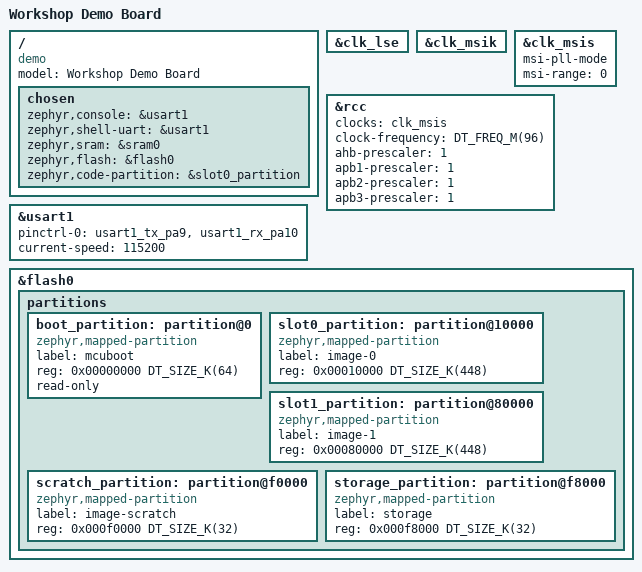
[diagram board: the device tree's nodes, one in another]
/dts-v1/;
#include <st/u3/stm32u385Xg.dtsi>
#include <st/u3/stm32u385rgtxq-pinctrl.dtsi>

/ {
	model = "Workshop Demo Board";
	compatible = "demo";

	chosen {
		zephyr,console = &usart1;
		zephyr,shell-uart = &usart1;
		zephyr,sram = &sram0;
		zephyr,flash = &flash0;
		zephyr,code-partition = &slot0_partition;
	};
};

// MSIS requires LSE clock to be enabled for auto-calibration
&clk_lse {
	status = "okay";
};

// Currently unused, but produces compiler warning if disabled
&clk_msik {
	status = "okay";
};

&clk_msis {
	status = "okay";
	msi-pll-mode;
	msi-range = <0>; /* 96MHz (reset value) */
};

&rcc {
	clocks = <&clk_msis>;
	clock-frequency = <DT_FREQ_M(96)>;
	ahb-prescaler = <1>;
	apb1-prescaler = <1>;
	apb2-prescaler = <1>;
	apb3-prescaler = <1>;
};

&usart1 {
	pinctrl-0 = <&usart1_tx_pa9 &usart1_rx_pa10>;
	pinctrl-names = "default";
	current-speed = <115200>;
	status = "okay";
};

&flash0 {
	ranges = <0x0 0x08000000 DT_SIZE_K(1024)>;
	#address-cells = <1>;
	#size-cells = <1>;

	partitions {
		ranges;
		#address-cells = <1>;
		#size-cells = <1>;

		boot_partition: partition@0 {
			compatible = "zephyr,mapped-partition";
			label = "mcuboot";
			reg = <0x00000000 DT_SIZE_K(64)>;
			read-only;
		};

		slot0_partition: partition@10000 {
			compatible = "zephyr,mapped-partition";
			label = "image-0";
			reg = <0x00010000 DT_SIZE_K(448)>;
		};

		slot1_partition: partition@80000 {
			compatible = "zephyr,mapped-partition";
			label = "image-1";
			reg = <0x00080000 DT_SIZE_K(448)>;
		};

		// used by "swap using scratch" strategy
		scratch_partition: partition@f0000 {
			compatible = "zephyr,mapped-partition";
			label = "image-scratch";
			reg = <0x000f0000 DT_SIZE_K(32)>;
		};

		storage_partition: partition@f8000 {
			compatible = "zephyr,mapped-partition";
			label = "storage";
			reg = <0x000f8000 DT_SIZE_K(32)>;
		};
	};
};
